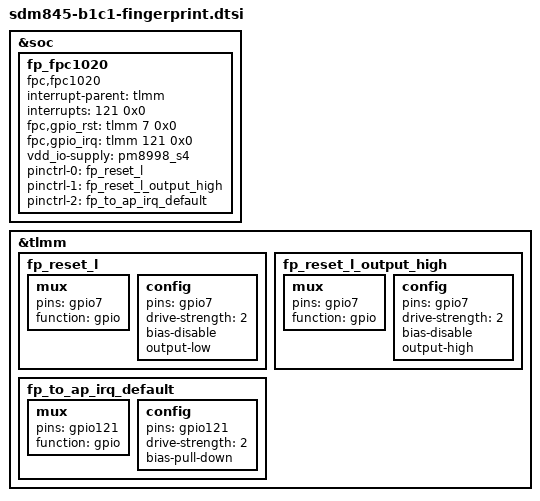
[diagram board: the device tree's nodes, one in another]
/* Copyright (c) 2017, The Linux Foundation. All rights reserved.
 *
 * This program is free software; you can redistribute it and/or modify
 * it under the terms of the GNU General Public License version 2 and
 * only version 2 as published by the Free Software Foundation.
 *
 * This program is distributed in the hope that it will be useful,
 * but WITHOUT ANY WARRANTY; without even the implied warranty of
 * MERCHANTABILITY or FITNESS FOR A PARTICULAR PURPOSE.  See the
 * GNU General Public License for more details.
 */

&soc {
	fp_fpc1020 {
		status = "ok";
		compatible = "fpc,fpc1020";
		interrupt-parent = <&tlmm>;
		interrupts = <121 0x0>;
		fpc,gpio_rst    = <&tlmm 7 0x0>;
		fpc,gpio_irq    = <&tlmm 121 0x0>;
		vdd_io-supply   = <&pm8998_s4>;

		pinctrl-names = "fpc1020_reset_reset",
			"fpc1020_reset_active",
			"fpc1020_irq_active";

		pinctrl-0 = <&fp_reset_l>;
		pinctrl-1 = <&fp_reset_l_output_high>;
		pinctrl-2 = <&fp_to_ap_irq_default>;
	};
};

&tlmm {
	fp_reset_l: fp_reset_l {
		mux {
			 pins = "gpio7";
			 function = "gpio";
		};

		config {
			pins = "gpio7";
			drive-strength = <2>;
			bias-disable;
			output-low;
		};
	};

	fp_reset_l_output_high: fp_reset_l_output_high {
		mux {
			pins = "gpio7";
			function = "gpio";
		};

		config {
			pins = "gpio7";
			drive-strength = <2>;
			bias-disable;
			output-high;
		};
	};

	fp_to_ap_irq_default: fp_to_ap_irq_default {
		mux {
			pins = "gpio121";
			function = "gpio";
		};

		config {
			pins = "gpio121";
			drive-strength = <2>;
			bias-pull-down;
		};
	};
};
